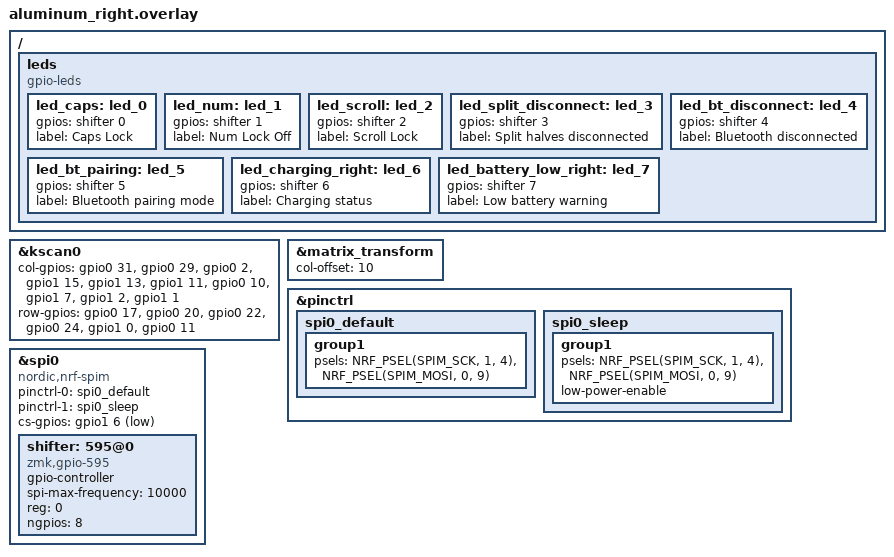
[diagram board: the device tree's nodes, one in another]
#include "aluminum.dtsi"

&kscan0 {
    col-gpios
        = <&gpio0 31 GPIO_ACTIVE_HIGH>
        , <&gpio0 29 GPIO_ACTIVE_HIGH>
        , <&gpio0 2 GPIO_ACTIVE_HIGH>
        , <&gpio1 15 GPIO_ACTIVE_HIGH>
        , <&gpio1 13 GPIO_ACTIVE_HIGH>
        , <&gpio1 11 GPIO_ACTIVE_HIGH>
        , <&gpio0 10 GPIO_ACTIVE_HIGH>
        , <&gpio1 7 GPIO_ACTIVE_HIGH>
        , <&gpio1 2 GPIO_ACTIVE_HIGH>
        , <&gpio1 1 GPIO_ACTIVE_HIGH>
        ;
    row-gpios
        = <&gpio0 17 GPIO_ACTIVE_HIGH>
        , <&gpio0 20 GPIO_ACTIVE_HIGH>
        , <&gpio0 22 GPIO_ACTIVE_HIGH>
        , <&gpio0 24 GPIO_ACTIVE_HIGH>
        , <&gpio1 0 GPIO_ACTIVE_HIGH>
        , <&gpio0 11 GPIO_ACTIVE_HIGH>
        ;
};

&matrix_transform {
    col-offset = <10>;
};

&pinctrl {
    /* configuration for spi0 device, default state */
    spi0_default: spi0_default {
        /* node name is arbitrary */
        group1 {
            /* main role: configure P1.01 as SPI clock, P1.06 as SPI MOSI, don't use SPI MISO */
            psels = <NRF_PSEL(SPIM_SCK, 1, 4)>,
                    <NRF_PSEL(SPIM_MOSI, 0, 9)>;
        };
    };

    /* configuration for spi0 device, sleep state */
    spi0_sleep: spi0_sleep {
        group1 {
            /* main role: configure P1.01 as SPI clock, P1.06 as SPI MOSI, don't use SPI MISO */
            psels = <NRF_PSEL(SPIM_SCK, 1, 4)>,
                    <NRF_PSEL(SPIM_MOSI, 0, 9)>;
            low-power-enable;
        };
    };
};

&spi0 {
    compatible = "nordic,nrf-spim";
    pinctrl-0 = <&spi0_default>;
    pinctrl-1 = <&spi0_sleep>;
    pinctrl-names = "default", "sleep";
};

&spi0 {
    status = "okay";
    cs-gpios = <&gpio1 6 GPIO_ACTIVE_LOW>;
    shifter: 595@0 {
        compatible = "zmk,gpio-595";
        status = "okay";
        gpio-controller;
        spi-max-frequency = <10000>; /*Decreased this to 10 kHz because I used low frequency pins like a n00b*/
        reg = <0>;
        #gpio-cells = <2>; 
        ngpios = <8>;
    };
};

/ {
    leds {
        compatible = "gpio-leds";
        led_caps: led_0 {
            gpios = <&shifter 0 GPIO_ACTIVE_HIGH>;
            label = "Caps Lock";
        };
        led_num: led_1 {
            gpios = <&shifter 1 GPIO_ACTIVE_HIGH>;
            label = "Num Lock Off";
        };
        led_scroll: led_2 {
            gpios = <&shifter 2 GPIO_ACTIVE_HIGH>;
            label = "Scroll Lock";
        };
        led_split_disconnect: led_3 {
            gpios = <&shifter 3 GPIO_ACTIVE_HIGH>;
            label = "Split halves disconnected";
        };
        led_bt_disconnect: led_4 {
            gpios = <&shifter 4 GPIO_ACTIVE_HIGH>;
            label = "Bluetooth disconnected";
        };
        led_bt_pairing: led_5 {
            gpios = <&shifter 5 GPIO_ACTIVE_HIGH>;
            label = "Bluetooth pairing mode";
        };
        led_charging_right: led_6 {
            gpios = <&shifter 6 GPIO_ACTIVE_HIGH>;
            label = "Charging status";
        };
        led_battery_low_right: led_7 {
            gpios = <&shifter 7 GPIO_ACTIVE_HIGH>;
            label = "Low battery warning";
        };
    };
};
